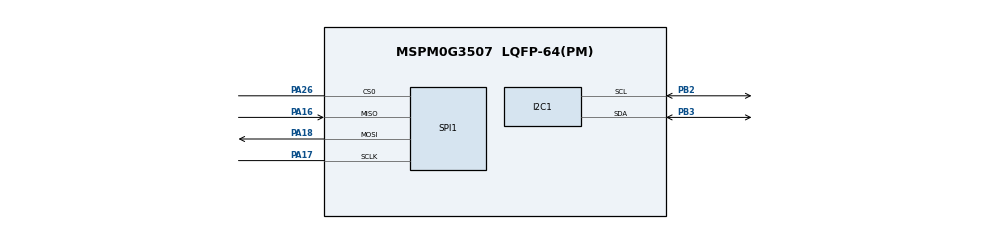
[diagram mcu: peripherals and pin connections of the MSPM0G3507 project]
//@cliArgs --device "MSPM0G350X" --package "LQFP-64(PM)" --part "Default"
//@v2CliArgs --device "MSPM0G3507" --package "LQFP-64(PM)"
// @cliArgs --board /ti/boards/LP_MSPM0G3507 --rtos nortos

/**
 * Import the modules used in this configuration.
 */
const I2C  = scripting.addModule("/ti/driverlib/I2C", {}, false);
const I2C1 = I2C.addInstance();
const SPI  = scripting.addModule("/ti/driverlib/SPI", {}, false);
const SPI1 = SPI.addInstance();

/**
 * Write custom configuration values to the imported modules.
 */
I2C1.$name                             = "I2C";
I2C1.basicEnableTarget                 = true;
I2C1.basicTargetAddress                = 0x48;
I2C1.advAnalogGlitchFilter             = "DISABLED";
I2C1.advTargetTXFIFOTRIG               = "BYTES_1";
I2C1.intTarget                         = ["ARBITRATION_LOST","INTERRUPT_OVERFLOW ","RXFIFO_OVERFLOW","RXFIFO_TRIGGER","START","STOP","TXFIFO_TRIGGER","TXFIFO_UNDERFLOW"];
I2C1.peripheral.$assign                = "I2C1";
I2C1.peripheral.sdaPin.$assign         = "PB3";
I2C1.peripheral.sclPin.$assign         = "PB2";
I2C1.sdaPinConfig.enableConfig         = true;
I2C1.sdaPinConfig.internalResistor     = "PULL_UP";
I2C1.sclPinConfig.enableConfig         = true;
I2C1.sclPinConfig.internalResistor     = "PULL_UP";

const Board = scripting.addModule("/ti/driverlib/Board", {}, false);

SPI1.rxFifoThreshold                    = "DL_SPI_RX_FIFO_LEVEL_ONE_FRAME";
SPI1.targetBitRate                      = 1000000;
SPI1.txFifoThreshold                    = "DL_SPI_TX_FIFO_LEVEL_3_4_EMPTY";
SPI1.$name                              = "SPI";
SPI1.enabledInterrupts                  = ["RX","TX"];
SPI1.peripheral.$assign                 = "SPI1";
SPI1.peripheral.sclkPin.$assign         = "PA17";
SPI1.peripheral.mosiPin.$assign         = "PA18";
SPI1.peripheral.misoPin.$assign         = "PA16";
SPI1.peripheral.cs0Pin.$assign          = "PA26";

const SYSCTL                 = scripting.addModule("/ti/driverlib/SYSCTL", {}, false);
SYSCTL.forceDefaultClkConfig = true;
SYSCTL.clockTreeEn           = true;
